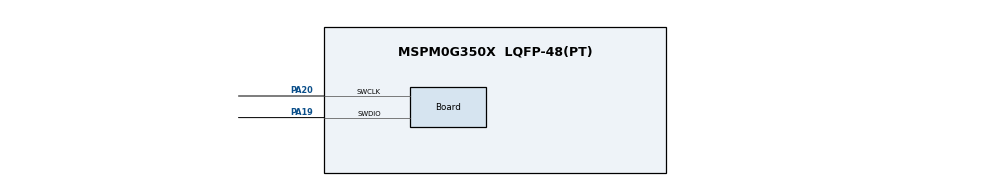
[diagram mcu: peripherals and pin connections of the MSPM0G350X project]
/**
 * @cliArgs --device "MSPM0G350X" --package "LQFP-48(PT)" --part "Default" --product "mspm0_sdk@2.01.00.03"
 * @versions {"tool":"1.20.0+3587"}
 */

/**
 * Import the modules used in this configuration.
 */
const GPIO          = scripting.addModule("/ti/driverlib/GPIO", {}, false);
const GPIO1         = GPIO.addInstance();
const SYSCTL        = scripting.addModule("/ti/driverlib/SYSCTL");
const TIMER         = scripting.addModule("/ti/driverlib/TIMER", {}, false);
const TIMER1        = TIMER.addInstance();
const ProjectConfig = scripting.addModule("/ti/project_config/ProjectConfig");

/**
 * Write custom configuration values to the imported modules.
 */
GPIO1.$name                          = "GPIO_LED";
GPIO1.associatedPins[0].$name        = "PIN_D2";
GPIO1.associatedPins[0].assignedPort = "PORTA";
GPIO1.associatedPins[0].assignedPin  = "14";

const Board                       = scripting.addModule("/ti/driverlib/Board", {}, false);
Board.peripheral.$assign          = "DEBUGSS";
Board.peripheral.swclkPin.$assign = "PA20";
Board.peripheral.swdioPin.$assign = "PA19";

SYSCTL.forceDefaultClkConfig = true;
SYSCTL.peripheral.$assign    = "SYSCTL";

TIMER1.$name            = "TIMER_TEST";
TIMER1.timerClkDiv      = 8;
TIMER1.timerPeriod      = "500 ms";
TIMER1.timerClkPrescale = 200;
TIMER1.timerMode        = "PERIODIC_UP";
TIMER1.timerStartTimer  = true;
TIMER1.interrupts       = ["LOAD"];

ProjectConfig.deviceSpin = "MSPM0G3507";

/**
 * Pinmux solution for unlocked pins/peripherals. This ensures that minor changes to the automatic solver in a future
 * version of the tool will not impact the pinmux you originally saw.  These lines can be completely deleted in order to
 * re-solve from scratch.
 */
GPIO1.associatedPins[0].pin.$suggestSolution = "PA14";
TIMER1.peripheral.$suggestSolution           = "TIMA0";
